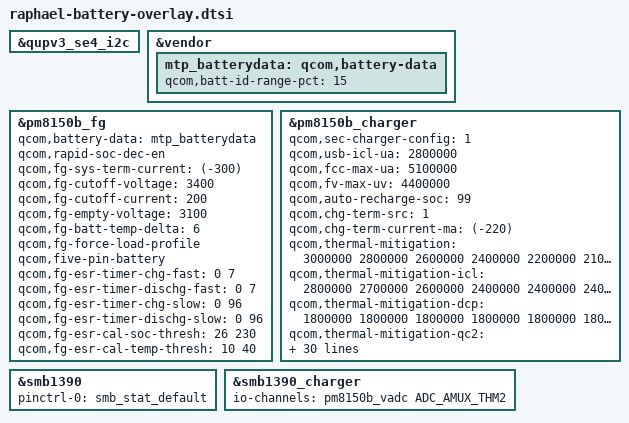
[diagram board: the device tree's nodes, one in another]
/* Copyright (c) 2020, The Linux Foundation. All rights reserved.
 *
 * This program is free software; you can redistribute it and/or modify
 * it under the terms of the GNU General Public License version 2 and
 * only version 2 as published by the Free Software Foundation.
 *
 * This program is distributed in the hope that it will be useful,
 * but WITHOUT ANY WARRANTY; without even the implied warranty of
 * MERCHANTABILITY or FITNESS FOR A PARTICULAR PURPOSE.  See the
 * GNU General Public License for more details.
 */

&qupv3_se4_i2c {
	#include "../qcom-base/smb1390.dtsi"
};

&vendor {
	mtp_batterydata: qcom,battery-data {
		qcom,batt-id-range-pct = <15>;
		#include "battery/batterydata-F11-sun-4000mah.dtsi"
		#include "battery/batterydata-F11-gyu-4000mah.dtsi"
	};
};

&pm8150b_fg {
	qcom,battery-data = <&mtp_batterydata>;
	qcom,rapid-soc-dec-en;
	qcom,fg-sys-term-current = <(-300)>;
	qcom,fg-cutoff-voltage = <3400>;
	qcom,fg-cutoff-current = <200>;
	qcom,fg-empty-voltage = <3100>;
	qcom,fg-batt-temp-delta = <6>;
	qcom,fg-force-load-profile;
	qcom,five-pin-battery;
	/* ESR fast calibration */
	qcom,fg-esr-timer-chg-fast = <0 7>;
	qcom,fg-esr-timer-dischg-fast = <0 7>;
	qcom,fg-esr-timer-chg-slow = <0 96>;
	qcom,fg-esr-timer-dischg-slow = <0 96>;
	qcom,fg-esr-cal-soc-thresh = <26 230>;
	qcom,fg-esr-cal-temp-thresh = <10 40>;
};

&pm8150b_charger {
	qcom,sec-charger-config = <1>;
	qcom,usb-icl-ua = <2800000>;
	qcom,fcc-max-ua = <5100000>;
	qcom,fv-max-uv = <4400000>;
	qcom,auto-recharge-soc = <99>;
	qcom,chg-term-src = <1>;
	qcom,chg-term-current-ma = <(-220)>;
	qcom,thermal-mitigation = <3000000 2800000 2600000 2400000 2200000 2100000 2000000
				   1800000 1600000 1500000 1400000 1200000 1000000 900000
				   800000 500000>;
	qcom,thermal-mitigation-icl
				= <2800000 2700000 2600000 2400000 2400000 2400000 2400000
				   2400000 2400000 2100000 1900000 1700000 1500000 1300000
				   1000000 750000>;
	qcom,thermal-mitigation-dcp
				= <1800000 1800000 1800000 1800000 1800000 1800000 1800000
				   1800000 1800000 1700000 1600000 1400000 1200000 1100000
				   1100000 1000000>;
	qcom,thermal-mitigation-qc2
				= <1500000 1500000 1500000 1500000 1450000 1400000 1350000
				   1300000 1300000 1200000 1000000 900000 850000 750000
				   650000 500000>;
	qcom,thermal-fcc-qc3-normal
				= <3200000 3000000 2800000 2600000 2500000 2400000 2300000
				   2200000 2100000 1800000 1600000 1400000 1200000 1000000
				   750000 750000>;
	qcom,thermal-fcc-qc3-cp
				= <3600000 3600000 3600000 3500000 3400000 3300000 3300000
				   3200000 3100000 2800000 2400000 2200000 2000000 1300000
				   1000000 700000>;
	qcom,thermal-fcc-qc3-classb-cp
				= <5100000 4800000 4600000 4400000 4200000 4000000 4000000
				   4000000 4000000 3600000 3400000 3200000 3000000 2200000
				   1000000 700000>;
	qcom,thermal-mitigation-pd-base
				= <3000000 2800000 2600000 2500000 2500000 2500000 2500000
				   2500000 2500000 2400000 2200000 2000000 1600000 1300000
				   1000000 500000>;
	qcom,thermal-fcc-pps-cp
				= <5100000 5000000 4900000 4800000 4600000 4400000 4200000
				   4000000 3800000 3600000 3400000 3200000 3000000 2200000
				   1000000 500000>;
	qcom,thermal-mitigation-dc
				= <2200000 2000000 1800000 1600000 1400000 1200000 1100000
				   1000000 900000  800000  700000  600000  500000  400000
				   300000  200000>;
	qcom,lpd_hwversion
				= <43200 53600 100000 121000 232000 300000 562000 900000>;

	io-channels = <&pm8150b_vadc ADC_MID_CHG_DIV6>,
		      <&pm8150b_vadc ADC_USB_IN_V_16>,
		      <&pm8150b_vadc ADC_USB_IN_I>,
		      <&pm8150b_vadc ADC_SBUx>,
		      <&pm8150b_vadc ADC_VPH_PWR>,
		      <&pm8150b_vadc ADC_CHG_TEMP>,
		      <&pm8150l_vadc ADC_GPIO1_PU2>,
		       <&pm8150l_vadc ADC_GPIO2_PU2>;

	io-channel-names = "mid_voltage",
			   "usb_in_voltage",
			   "usb_in_current",
			   "sbux_res",
			   "vph_voltage",
			   "chg_temp",
			   "hw_version_gpio5",
			   "project_gpio6";

	qcom,battery-data = <&mtp_batterydata>;
	dpdm-supply = <&usb2_phy0>;
	qcom,distinguish-qc-class-ab;
	qcom,lpd-disable;
	qcom,sw-jeita-enable;
	qcom,step-charging-enable;
	qcom,wd-bark-time-secs = <16>;
};

&smb1390 {
	pinctrl-names = "default";
	pinctrl-0 = <&smb_stat_default>;
	status = "ok";
};

&smb1390_charger {
	io-channels = <&pm8150b_vadc ADC_AMUX_THM2>;
	io-channel-names = "cp_die_temp";
	status = "ok";
};
